# CC1314R10 register map
File version: 1.0
CPU: CM33 1.0, other endian, MPU, FPU, 3 interrupt priority bits
Registers are 32-bit, read-write, reset 0x0 unless marked. A register's access mark holds for its fields unless they carry their own. Offsets are from the block's base; [hi:lo] are bit positions; {n}, {i} and the like mark numbered series.

## GPIO — MCU GPIO - I/F for controlling and reading IO status and IO event status
Base 0x40022000
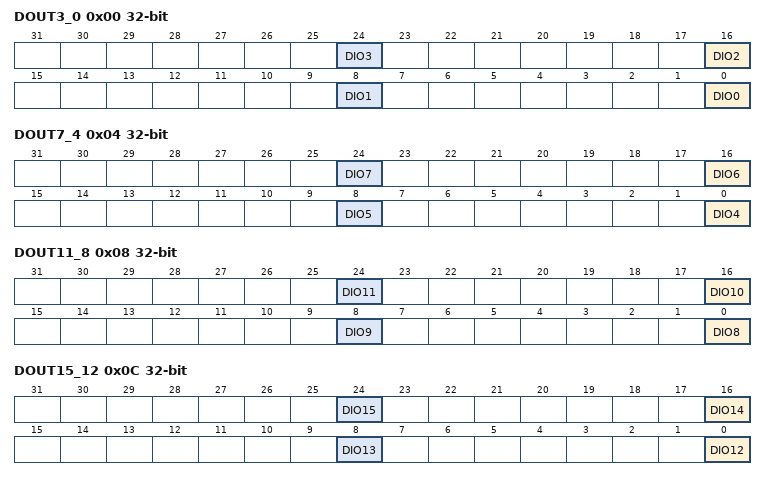
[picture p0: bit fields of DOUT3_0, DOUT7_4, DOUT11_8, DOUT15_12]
0x00 DOUT3_0 — Data Out 0 to 3 Alias register for byte access to each bit in DOUT47_0
  [8n] DIO{n} (n=0..3) — [{8n}:{8n}] Sets the state of the pin that is configured as DIO#{n}, if the corresponding DOE47_0 bitfield is set.
0x04 DOUT7_4 — Data Out 4 to 7 Alias register for byte access to each bit in DOUT47_0
  [8n-32] DIO{n} (n=4..7) — [{8n-32}:{8n-32}] Sets the state of the pin that is configured as DIO#{n}, if the corresponding DOE47_0 bitfield is set.
0x08 DOUT11_8 — Data Out 8 to 11 Alias register for byte access to each bit in DOUT47_0
  [8n-64] DIO{n} (n=8..11) — [{8n-64}:{8n-64}] Sets the state of the pin that is configured as DIO#{n}, if the corresponding DOE47_0 bitfield is set.
0x0C DOUT15_12 — Data Out 12 to 15 Alias register for byte access to each bit in DOUT47_0
  [8n-96] DIO{n} (n=12..15) — [{8n-96}:{8n-96}] Sets the state of the pin that is configured as DIO#{n}, if the corresponding DOE47_0 bitfield is set.
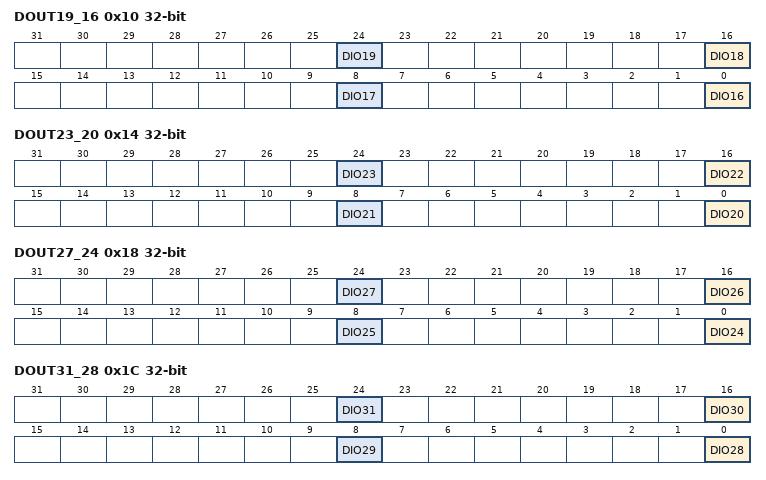
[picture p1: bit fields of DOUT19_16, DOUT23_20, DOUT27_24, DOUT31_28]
0x10 DOUT19_16 — Data Out 16 to 19 Alias register for byte access to each bit in DOUT47_0
  [8n-128] DIO{n} (n=16..19) — [{8n-128}:{8n-128}] Sets the state of the pin that is configured as DIO#{n}, if the corresponding DOE47_0 bitfield is set.
0x14 DOUT23_20 — Data Out 20 to 23 Alias register for byte access to each bit in DOUT47_0
  [8n-160] DIO{n} (n=20..23) — [{8n-160}:{8n-160}] Sets the state of the pin that is configured as DIO#{n}, if the corresponding DOE47_0 bitfield is set.
0x18 DOUT27_24 — Data Out 24 to 27 Alias register for byte access to each bit in DOUT47_0
  [8n-192] DIO{n} (n=24..27) — [{8n-192}:{8n-192}] Sets the state of the pin that is configured as DIO#{n}, if the corresponding DOE47_0 bitfield is set.
0x1C DOUT31_28 — Data Out 28 to 31 Alias register for byte access to each bit in DOUT47_0
  [8n-224] DIO{n} (n=28..31) — [{8n-224}:{8n-224}] Sets the state of the pin that is configured as DIO#{n}, if the corresponding DOE47_0 bitfield is set.
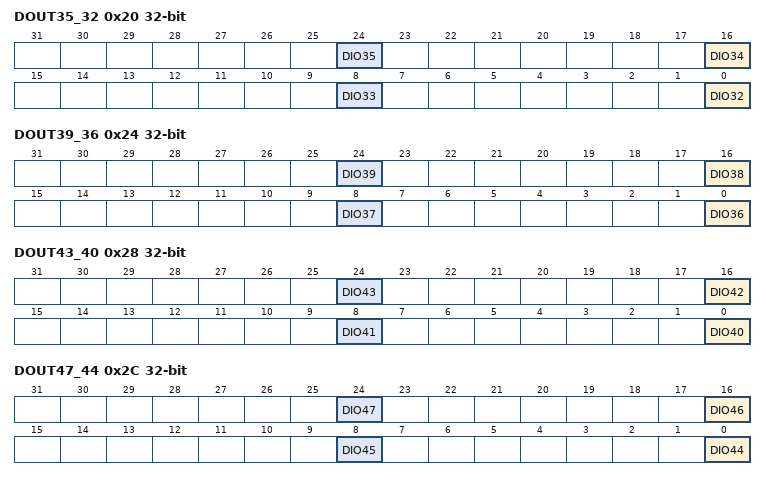
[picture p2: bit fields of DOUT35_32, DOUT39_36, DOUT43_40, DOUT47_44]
0x20 DOUT35_32 — Data Out 35 to 32 Alias register for byte access to each bit in DOUT47_0
  [8n-256] DIO{n} (n=32..35) — [{8n-256}:{8n-256}] Sets the state of the pin that is configured as DIO#{n}, if the corresponding DOE47_0 bitfield is set.
0x24 DOUT39_36 — Data Out 39 to 36 Alias register for byte access to each bit in DOUT47_0
  [8n-288] DIO{n} (n=36..39) — [{8n-288}:{8n-288}] Sets the state of the pin that is configured as DIO#{n}, if the corresponding DOE47_0 bitfield is set.
0x28 DOUT43_40 — Data Out 43 to 40 Alias register for byte access to each bit in DOUT47_0
  [8n-320] DIO{n} (n=40..43) — [{8n-320}:{8n-320}] Sets the state of the pin that is configured as DIO#{n}, if the corresponding DOE47_0 bitfield is set.
0x2C DOUT47_44 — Data Out 47 to 44 Alias register for byte access to each bit in DOUT47_0
  [8n-352] DIO{n} (n=44..47) — [{8n-352}:{8n-352}] Sets the state of the pin that is configured as DIO#{n}, if the corresponding DOE47_0 bitfield is set.
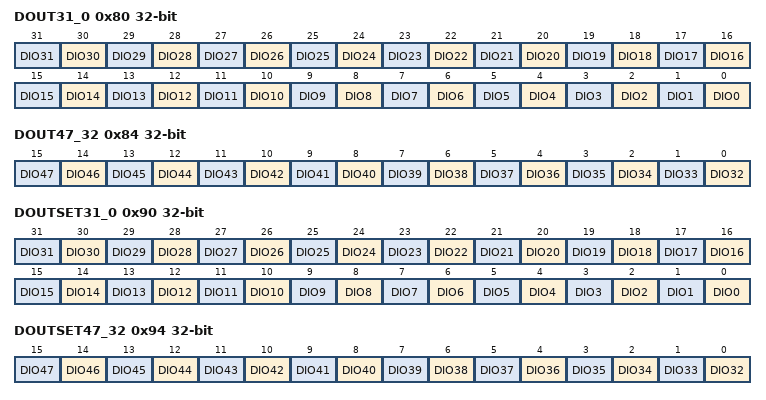
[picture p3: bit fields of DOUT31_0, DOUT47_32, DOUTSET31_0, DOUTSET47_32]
0x80 DOUT31_0 — Data Output for DIO 0 to 31
  [n] DIO{n} (n=0..31) — [{n}:{n}] Data output for DIO {n}
0x84 DOUT47_32 — Data Output for DIO 0 to 31
  [n-32] DIO{n} (n=32..47) — [{n-32}:{n-32}] Data output for DIO {n}
0x90 DOUTSET31_0 — Data Out Set Writing 1 to a bit position sets the corresponding bit in the DOUT47_0 register
  [n] DIO{n} (n=0..31) — [{n}:{n}] Set bit {n}
0x94 DOUTSET47_32 — Data Out Set Writing 1 to a bit position sets the corresponding bit in the DOUT47_0 register
  [n-32] DIO{n} (n=32..47) — [{n-32}:{n-32}] Set bit {n}
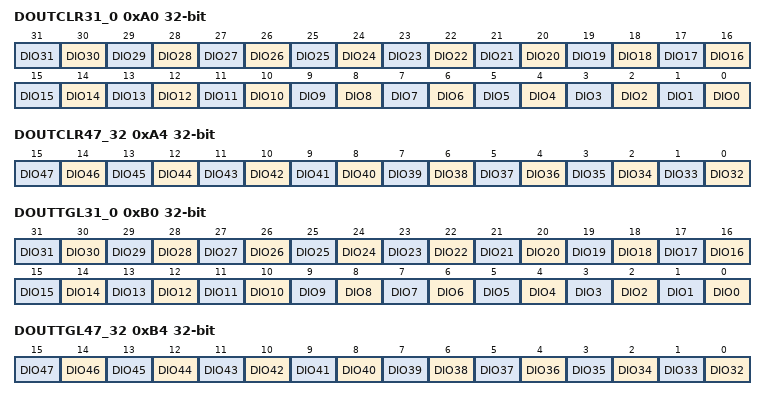
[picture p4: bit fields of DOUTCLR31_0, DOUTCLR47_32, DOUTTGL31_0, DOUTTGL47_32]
0xA0 DOUTCLR31_0 — Data Out Clear Writing 1 to a bit position clears the corresponding bit in the DOUT47_0 register
  [n] DIO{n} (n=0..31) — [{n}:{n}] Clears bit {n}
0xA4 DOUTCLR47_32 — Data Out Clear Writing 1 to a bit position clears the corresponding bit in the DOUT47_0 register
  [n-32] DIO{n} (n=32..47) — [{n-32}:{n-32}] Clears bit {n}
0xB0 DOUTTGL31_0 — Data Out Toggle Writing 1 to a bit position will invert the corresponding DIO output.
  [n] DIO{n} (n=0..31) — [{n}:{n}] Toggles bit {n}
0xB4 DOUTTGL47_32 — Data Out Toggle Writing 1 to a bit position will invert the corresponding DIO output.
  [n-32] DIO{n} (n=32..47) — [{n-32}:{n-32}] Toggles bit {n}
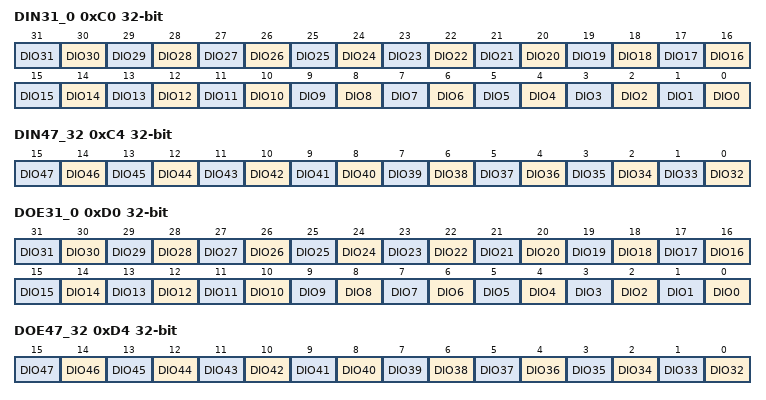
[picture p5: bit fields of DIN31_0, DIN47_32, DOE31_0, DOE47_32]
0xC0 DIN31_0 — Data Input from DIO 0 to 31
  [n] DIO{n} ro (n=0..31) — [{n}:{n}] Data input from DIO {n}
0xC4 DIN47_32 — Data Input from DIO 32 to 47
  [n-32] DIO{n} ro (n=32..47) — [{n-32}:{n-32}] Data input from DIO {n}
0xD0 DOE31_0 — Data Output Enable for DIO 0 to 31
  [n] DIO{n} (n=0..31) — [{n}:{n}] Data output enable for DIO {n}
0xD4 DOE47_32 — Data Output Enable for DIO 32 to 47
  [n-32] DIO{n} (n=32..47) — [{n-32}:{n-32}] Data output enable for DIO {n}
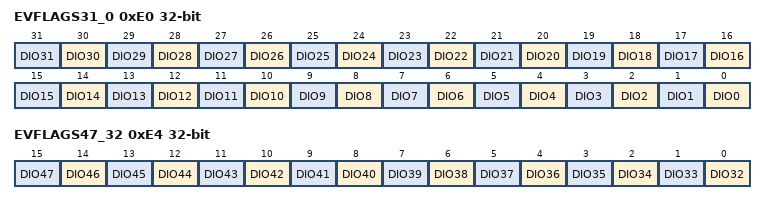
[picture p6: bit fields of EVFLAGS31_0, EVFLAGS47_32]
0xE0 EVFLAGS31_0 — Event Register for DIO 0 to 31 Reading this registers will return 1 for triggered event and 0 for non-triggered events. Writing a 1 to a bit field will clear the event. The configuration of events is done inside MCU IOC, e.g. events for DIO #0 is configured in IOC:IOCFG0.EDGE_DET and IOC:IOCFG0.EDGE_IRQ_EN.
  [n] DIO{n} (n=0..31) — [{n}:{n}] Event for DIO {n}
0xE4 EVFLAGS47_32 — Event Register for DIO 32 to 47 Reading this registers will return 1 for triggered event and 0 for non-triggered events. Writing a 1 to a bit field will clear the event. The configuration of events is done inside MCU IOC, e.g. events for DIO #0 is configured in IOC:IOCFG0.EDGE_DET and IOC:IOCFG0.EDGE_IRQ_EN.
  [n-32] DIO{n} (n=32..47) — [{n-32}:{n-32}] Event for DIO {n}
